# R7FA4W1AD register map
Vendor: Renesas; Series: RA4; File version: 1.0
CPU: CM4 r0p1, little endian, MPU, FPU, VTOR, 4 interrupt priority bits
Registers are 8-bit, read-write, reset 0x0 unless marked. A register's access mark holds for its fields unless they carry their own. Offsets are from the block's base; [hi:lo] are bit positions.

## CTSU — Capacitive Touch Sensing Unit
Base 0x40081000
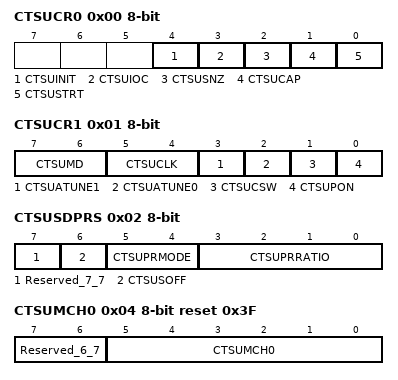
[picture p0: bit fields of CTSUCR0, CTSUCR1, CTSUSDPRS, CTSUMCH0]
0x00 CTSUCR0 — CTSU Control Register 0
  [4] CTSUINIT — CTSU Control Block Initialization
  [3] CTSUIOC — CTSU Transmit Pin Control
  [2] CTSUSNZ — CTSU Wait State Power,Saving Enable
  [1] CTSUCAP — CTSU Measurement Operation Start Trigger Select
  [0] CTSUSTRT — CTSU Measurement Operation Start
0x01 CTSUCR1 — CTSU Control Register 1
  [7:6] CTSUMD — CTSU Measurement Mode Select
  [5:4] CTSUCLK — CTSU Operating Clock Select
  [3] CTSUATUNE1 — CTSU Power Supply Capacity Adjustment
  [2] CTSUATUNE0 — CTSU Power Supply Operating Mode Setting
  [1] CTSUCSW — CTSU LPF Capacitance Charging Control
  [0] CTSUPON — CTSU Power Supply Enable
0x02 CTSUSDPRS — CTSU Synchronous Noise Reduction Setting Register
  [7] Reserved_7_7 — This bit is read as 0. The write value should be 0.
  [6] CTSUSOFF — CTSU High,Pass Noise Reduction Function Off Setting
  [5:4] CTSUPRMODE — CTSU Base Period and Pulse Count Setting
  [3:0] CTSUPRRATIO — CTSU Measurement Time and Pulse Count AdjustmentRecommended setting: 3 (0011b)
0x03 CTSUSST — CTSU Sensor Stabilization Wait Control Register
  [7:0] CTSUSST — CTSU Sensor Stabilization Wait ControlNOTE: The value of these bits should be fixed to 00010000b.
0x04 CTSUMCH0 reset 0x3F — CTSU Measurement Channel Register 0
  [7:6] Reserved_6_7 — These bits are read as 00. The write value should be 00.
  [5:0] CTSUMCH0 — CTSU Measurement Channel 0.Note1: Writing to these bits is only enabled in self,capacitance single,scan mode (CTSUCR1.CTSUMD[1:0] bits = 00b).Note2: If the value of CTSUMCH0 was set to b'111111 in mode other than self,capacitor single scan mode, the measurement is stopped.
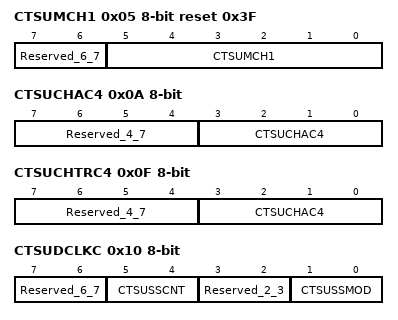
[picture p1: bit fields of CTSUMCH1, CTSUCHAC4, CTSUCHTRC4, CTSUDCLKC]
0x05 CTSUMCH1 reset 0x3F — CTSU Measurement Channel Register 1
  [7:6] Reserved_6_7 — These bits are read as 00. The write value should be 00.
  [5:0] CTSUMCH1 ro — CTSU Measurement Channel 1Note1: If the value of CTSUMCH1 was set to b'111111, the measurement is stopped.
0x06 CTSUCHAC0 — CTSU Channel Enable Control Register 0
  [7:0] CTSUCHAC0 — CTSU Channel Enable Control 0.0: Not measurement target1: Measurement targetNote: CTSUCHAC0[0] corresponds to TS00 and CTSUCHAC0[7] corresponds to TS07. but the write value of CTSUCHAC0[2] should be 0.
0x07 CTSUCHAC1 — CTSU Channel Enable Control Register 1
  [7:0] CTSUCHAC1 — CTSU Channel Enable Control 1.0: Not measurement target1: Measurement targetNote: CTSUCHAC1[0] corresponds to TS08 and CTSUCHAC1[7] corresponds to TS15.
0x08 CTSUCHAC2 — CTSU Channel Enable Control Register 2
  [7:0] CTSUCHAC2 — CTSU Channel Enable Control 2.0: Not measurement target1: Measurement targetNote: CTSUCHAC2[0] corresponds to TS16 and CTSUCHAC2[7] corresponds to TS23.
0x09 CTSUCHAC3 — CTSU Channel Enable Control Register 3
  [7:0] CTSUCHAC3 — CTSU Channel Enable Control 3.0: Not measurement target1: Measurement targetNote: CTSUCHAC3[0] corresponds to TS24 and CTSUCHAC3[7] corresponds to TS31.
0x0A CTSUCHAC4 — CTSU Channel Enable Control Register 4
  [7:4] Reserved_4_7 — These bits are read as 0000. The write value should be 0000.
  [3:0] CTSUCHAC4 — CTSU Channel Enable Control 4.0: Not measurement target1: Measurement targetNote: CTSUCHAC4[0] corresponds to TS32 and CTSUCHAC4[3] corresponds to TS35. but the write value of CTSUCHAC0[4],CTSUCHAC4[5],CTSUCHAC4[6],CTSUCHAC4[7] should be 0.
0x0B CTSUCHTRC0 — CTSU Channel Transmit/Receive Control Register 0
  [7:0] CTSUCHTRC0 — CTSU Channel Transmit/Receive Control 0
0x0C CTSUCHTRC1 — CTSU Channel Transmit/Receive Control Register 1
  [7:0] CTSUCHTRC1 — CTSU Channel Transmit/Receive Control 1
0x0D CTSUCHTRC2 — CTSU Channel Transmit/Receive Control Register 3
  [7:0] CTSUCHTRC2 — CTSU Channel Transmit/Receive Control 2
0x0E CTSUCHTRC3 — CTSU Channel Transmit/Receive Control Register 3
  [7:0] CTSUCHTRC3 — CTSU Channel Transmit/Receive Control 3
0x0F CTSUCHTRC4 — CTSU Channel Transmit/Receive Control Register 4
  [7:4] Reserved_4_7 — These bits are read as 0000. The write value should be 0000.
  [3:0] CTSUCHAC4 — CTSU Channel Transmit/Receive Control 4
0x10 CTSUDCLKC — CTSU High,Pass Noise Reduction Control Register
  [7:6] Reserved_6_7 — These bits are read as 00. The write value should be 00.
  [5:4] CTSUSSCNT — CTSU Diffusion Clock Mode ControlNOTE: This bit should be set to 11b.
  [3:2] Reserved_2_3 — These bits are read as 00. The write value should be 00.
  [1:0] CTSUSSMOD — CTSU Diffusion Clock Mode SelectNOTE: This bit should be set to 00b.
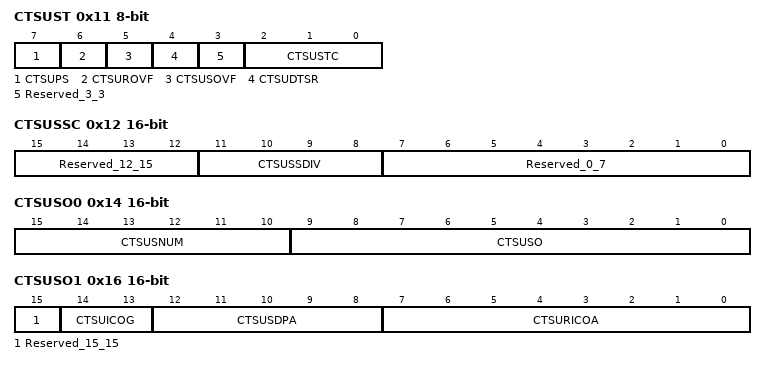
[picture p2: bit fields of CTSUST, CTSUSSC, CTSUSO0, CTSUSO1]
0x11 CTSUST — CTSU Status Register
  [7] CTSUPS ro — CTSU Mutual Capacitance Status Flag
  [6] CTSUROVF — CTSU Reference Counter Overflow Flag
  [5] CTSUSOVF — CTSU Sensor Counter Overflow Flag
  [4] CTSUDTSR ro — CTSU Data Transfer Status Flag
  [3] Reserved_3_3 — This bit is read as 0. The write value should be 0.
  [2:0] CTSUSTC — CTSU Measurement Status Counter
0x12 CTSUSSC 16-bit — CTSU High,Pass Noise Reduction Spectrum Diffusion Control Register
  [15:12] Reserved_12_15 — These bits are read as 0000. The write value should be 0000.
  [11:8] CTSUSSDIV — CTSU Spectrum Diffusion Frequency Division Setting
  [7:0] Reserved_0_7 — These bits are read as 00000000. The write value should be 00000000.
0x14 CTSUSO0 16-bit — CTSU Sensor Offset Register 0
  [15:10] CTSUSNUM — CTSU Measurement Count Setting
  [9:0] CTSUSO — CTSU Sensor Offset AdjustmentCurrent offset amount is CTSUSO ( 0 to 1023 )
0x16 CTSUSO1 16-bit — CTSU Sensor Offset Register 1
  [15] Reserved_15_15 — This bit is read as 0. The write value should be 0.
  [14:13] CTSUICOG — CTSU ICO Gain Adjustment
  [12:8] CTSUSDPA — CTSU Base Clock SettingOperating clock divided by ( CTSUSDPA + 1 ) x 2
  [7:0] CTSURICOA — CTSU Reference ICO Current AdjustmentCurrent offset amount is CTSUSO ( 0 to 255 )
0x18 CTSUSC 16-bit ro — CTSU Sensor Counter
  [15:0] CTSUSC — CTSU Sensor CounterThese bits indicate the measurement result of the CTSU. These bits indicate FFFFh when an overflow occurs.
0x1A CTSURC 16-bit ro — CTSU Reference Counter
  [15:0] CTSURC — CTSU Reference CounterThese bits indicate the measurement result of the reference ICO.These bits indicate FFFFh when an overflow occurs.
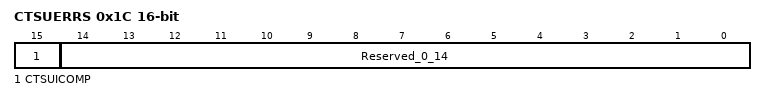
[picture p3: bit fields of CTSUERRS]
0x1C CTSUERRS 16-bit ro — CTSU Error Status Register
  [15] CTSUICOMP — TSCAP Voltage Error Monitor
  [14:0] Reserved_0_14 — These bits are read as 000000000000000.
